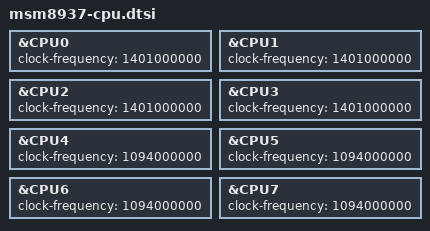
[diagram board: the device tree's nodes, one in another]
&CPU0 {
	clock-frequency = <1401000000>;
};

&CPU1 {
	clock-frequency = <1401000000>;
};

&CPU2 {
	clock-frequency = <1401000000>;
};

&CPU3 {
	clock-frequency = <1401000000>;
};

&CPU4 {
	clock-frequency = <1094000000>;
};

&CPU5 {
	clock-frequency = <1094000000>;
};

&CPU6 {
	clock-frequency = <1094000000>;
};

&CPU7 {
	clock-frequency = <1094000000>;
};

